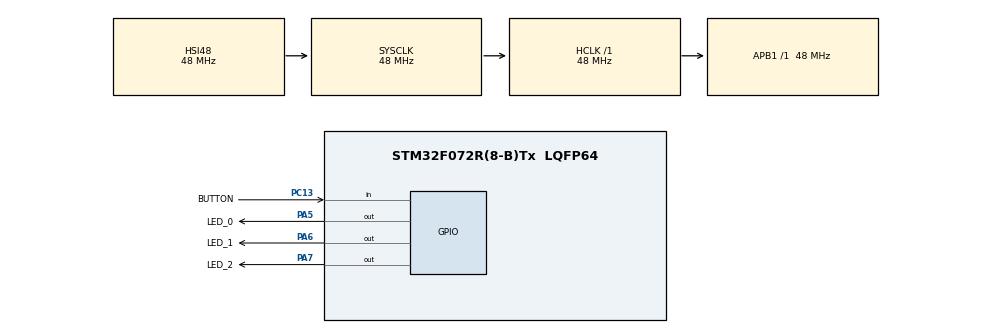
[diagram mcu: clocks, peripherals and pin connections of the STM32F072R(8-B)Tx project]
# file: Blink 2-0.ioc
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Mcu.Family=STM32F0
Mcu.Name=STM32F072R(8-B)Tx
Mcu.Package=LQFP64
PA13.Mode=Serial_Wire
PA13.Signal=SYS_SWDIO
PA14.Mode=Serial_Wire
PA14.Signal=SYS_SWCLK
PA5.GPIO_Label=LED_0
PA5.GPIO_Mode=GPIO_MODE_OUTPUT_PP
PA5.GPIO_ModeDefaultOutputPP=GPIO_MODE_OUTPUT_PP
PA5.GPIO_PuPd=GPIO_NOPULL
PA5.GPIO_Speed=GPIO_SPEED_FREQ_LOW
PA5.PinState=GPIO_PIN_RESET
PA5.Signal=GPIO_Output
PA6.GPIO_Label=LED_1
PA6.GPIO_ModeDefaultOutputPP=GPIO_MODE_OUTPUT_PP
PA6.GPIO_PuPd=GPIO_NOPULL
PA6.GPIO_Speed=GPIO_SPEED_FREQ_LOW
PA6.PinState=GPIO_PIN_RESET
PA6.Signal=GPIO_Output
PA7.GPIO_Label=LED_2
PA7.GPIO_ModeDefaultOutputPP=GPIO_MODE_OUTPUT_PP
PA7.GPIO_PuPd=GPIO_NOPULL
PA7.GPIO_Speed=GPIO_SPEED_FREQ_LOW
PA7.PinState=GPIO_PIN_RESET
PA7.Signal=GPIO_Output
PC13.GPIO_Label=BUTTON
PC13.GPIO_Mode=GPIO_MODE_INPUT
PC13.GPIO_PuPd=GPIO_NOPULL
PC13.Signal=GPIO_Input
PC14-OSC32_IN.Mode=LSE-External-Oscillator
PC14-OSC32_IN.Signal=RCC_OSC32_IN
PC15-OSC32_OUT.Mode=LSE-External-Oscillator
PC15-OSC32_OUT.Signal=RCC_OSC32_OUT
PF0-OSC_IN.Mode=HSE-External-Clock-Source
PF0-OSC_IN.Signal=RCC_OSC_IN
PF1-OSC_OUT.Signal=RCC_OSC_OUT
ProjectManager.HeapSize=0x200
ProjectManager.StackSize=0x400
ProjectManager.TargetToolchain=TrueSTUDIO
RCC.AHBFreq_Value=48000000
RCC.APB1Freq_Value=48000000
RCC.APB1TimFreq_Value=48000000
RCC.FLatency-AdvancedSettings=FLASH_LATENCY_1
RCC.HCLKFreq_Value=48000000
RCC.PLLDivider=RCC_PREDIV_DIV2
RCC.PLLMUL=RCC_PLL_MUL12
RCC.PREFETCH_ENABLE-AdvancedSettings=1
RCC.SYSCLKFreq_VALUE=48000000
RCC.SYSCLKSource=RCC_SYSCLKSOURCE_HSI48
RCC.USBFreq_Value=48000000
board=NUCLEO-F072RB

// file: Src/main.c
/* USER CODE BEGIN Header */
/**
  ******************************************************************************
  * @file           : main.c
  * @brief          : Main program body
  ******************************************************************************
  * @attention
  *
  * <h2><center>&copy; Copyright (c) 2019 STMicroelectronics.
  * All rights reserved.</center></h2>
  *
  * This software component is licensed by ST under BSD 3-Clause license,
  * the "License"; You may not use this file except in compliance with the
  * License. You may obtain a copy of the License at:
  *                        opensource.org/licenses/BSD-3-Clause
  *
  ******************************************************************************
  */
/* USER CODE END Header */

#include "main.h"

void SystemClock_Config(void);
static void MX_GPIO_Init(void);

int main(void)
{

  /* MCU Configuration--------------------------------------------------------*/

  /* Reset of all peripherals, Initializes the Flash interface and the Systick. */
  HAL_Init();

  /* Configure the system clock */
  SystemClock_Config();

  /* Initialize all configured peripherals */
  MX_GPIO_Init();

  /* Infinite loop */
  /* USER CODE BEGIN WHILE */
  while (1)
  {
	  HAL_GPIO_TogglePin(LED_0_GPIO_Port, LED_0_Pin);
	  HAL_Delay(166);
	  HAL_GPIO_TogglePin(LED_1_GPIO_Port, LED_1_Pin);
	  HAL_Delay(166);
	  HAL_GPIO_TogglePin(LED_2_GPIO_Port, LED_2_Pin);
	  HAL_Delay(167);
    /* USER CODE END WHILE */

  }
}

void SystemClock_Config(void)
{
  RCC_OscInitTypeDef RCC_OscInitStruct = {0};
  RCC_ClkInitTypeDef RCC_ClkInitStruct = {0};

  /** Initializes the CPU, AHB and APB busses clocks
  */
  RCC_OscInitStruct.OscillatorType = RCC_OSCILLATORTYPE_HSI48;
  RCC_OscInitStruct.HSI48State = RCC_HSI48_ON;
  RCC_OscInitStruct.PLL.PLLState = RCC_PLL_NONE;
  if (HAL_RCC_OscConfig(&RCC_OscInitStruct) != HAL_OK)
  {
    Error_Handler();
  }
  /** Initializes the CPU, AHB and APB busses clocks
  */
  RCC_ClkInitStruct.ClockType = RCC_CLOCKTYPE_HCLK|RCC_CLOCKTYPE_SYSCLK
                              |RCC_CLOCKTYPE_PCLK1;
  RCC_ClkInitStruct.SYSCLKSource = RCC_SYSCLKSOURCE_HSI48;
  RCC_ClkInitStruct.AHBCLKDivider = RCC_SYSCLK_DIV1;
  RCC_ClkInitStruct.APB1CLKDivider = RCC_HCLK_DIV1;

  if (HAL_RCC_ClockConfig(&RCC_ClkInitStruct, FLASH_LATENCY_1) != HAL_OK)
  {
    Error_Handler();
  }
}

static void MX_GPIO_Init(void)
{
  GPIO_InitTypeDef GPIO_InitStruct = {0};

  /* GPIO Ports Clock Enable */
  __HAL_RCC_GPIOC_CLK_ENABLE();
  __HAL_RCC_GPIOF_CLK_ENABLE();
  __HAL_RCC_GPIOA_CLK_ENABLE();

  /*Configure GPIO pin Output Level */
  HAL_GPIO_WritePin(GPIOA, LED_0_Pin|LED_1_Pin|LED_2_Pin, GPIO_PIN_RESET);

  /*Configure GPIO pin : BUTTON_Pin */
  GPIO_InitStruct.Pin = BUTTON_Pin;
  GPIO_InitStruct.Mode = GPIO_MODE_INPUT;
  GPIO_InitStruct.Pull = GPIO_NOPULL;
  HAL_GPIO_Init(BUTTON_GPIO_Port, &GPIO_InitStruct);

  /*Configure GPIO pins : LED_0_Pin LED_1_Pin LED_2_Pin */
  GPIO_InitStruct.Pin = LED_0_Pin|LED_1_Pin|LED_2_Pin;
  GPIO_InitStruct.Mode = GPIO_MODE_OUTPUT_PP;
  GPIO_InitStruct.Pull = GPIO_NOPULL;
  GPIO_InitStruct.Speed = GPIO_SPEED_FREQ_LOW;
  HAL_GPIO_Init(GPIOA, &GPIO_InitStruct);

}

void Error_Handler(void)
{
}

/************************ (C) COPYRIGHT STMicroelectronics *****END OF FILE****/
